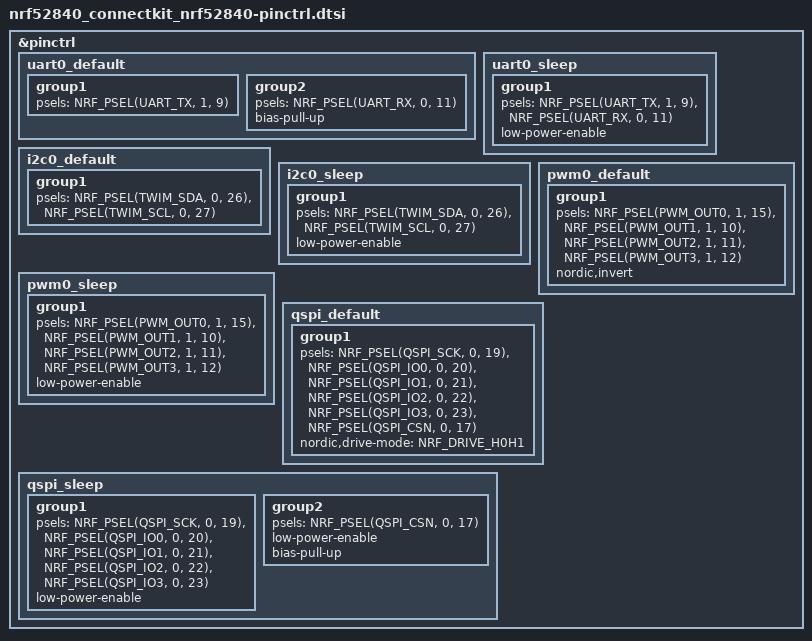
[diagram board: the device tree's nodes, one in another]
/*
 * Copyright (c) 2016-2025 Makerdiary <https://makerdiary.com>
 * SPDX-License-Identifier: Apache-2.0
 */

&pinctrl {
	uart0_default: uart0_default {
		group1 {
			psels = <NRF_PSEL(UART_TX, 1, 9)>;
		};
		group2 {
			psels = <NRF_PSEL(UART_RX, 0, 11)>;
			bias-pull-up;
		};
	};

	uart0_sleep: uart0_sleep {
		group1 {
			psels = <NRF_PSEL(UART_TX, 1, 9)>,
				<NRF_PSEL(UART_RX, 0, 11)>;
			low-power-enable;
		};
	};

	i2c0_default: i2c0_default {
		group1 {
			psels = <NRF_PSEL(TWIM_SDA, 0, 26)>,
				<NRF_PSEL(TWIM_SCL, 0, 27)>;
		};
	};

	i2c0_sleep: i2c0_sleep {
		group1 {
			psels = <NRF_PSEL(TWIM_SDA, 0, 26)>,
				<NRF_PSEL(TWIM_SCL, 0, 27)>;
			low-power-enable;
		};
	};

	pwm0_default: pwm0_default {
		group1 {
			psels = <NRF_PSEL(PWM_OUT0, 1, 15)>,
				<NRF_PSEL(PWM_OUT1, 1, 10)>,
				<NRF_PSEL(PWM_OUT2, 1, 11)>,
				<NRF_PSEL(PWM_OUT3, 1, 12)>;
			nordic,invert;
		};
	};

	pwm0_sleep: pwm0_sleep {
		group1 {
			psels = <NRF_PSEL(PWM_OUT0, 1, 15)>,
				<NRF_PSEL(PWM_OUT1, 1, 10)>,
				<NRF_PSEL(PWM_OUT2, 1, 11)>,
				<NRF_PSEL(PWM_OUT3, 1, 12)>;
			low-power-enable;
		};
	};

	qspi_default: qspi_default {
		group1 {
			psels = <NRF_PSEL(QSPI_SCK, 0, 19)>,
				<NRF_PSEL(QSPI_IO0, 0, 20)>,
				<NRF_PSEL(QSPI_IO1, 0, 21)>,
				<NRF_PSEL(QSPI_IO2, 0, 22)>,
				<NRF_PSEL(QSPI_IO3, 0, 23)>,
				<NRF_PSEL(QSPI_CSN, 0, 17)>;
			nordic,drive-mode = <NRF_DRIVE_H0H1>;
		};
	};

	qspi_sleep: qspi_sleep {
		group1 {
			psels = <NRF_PSEL(QSPI_SCK, 0, 19)>,
				<NRF_PSEL(QSPI_IO0, 0, 20)>,
				<NRF_PSEL(QSPI_IO1, 0, 21)>,
				<NRF_PSEL(QSPI_IO2, 0, 22)>,
				<NRF_PSEL(QSPI_IO3, 0, 23)>;
			low-power-enable;
		};
		group2 {
			psels = <NRF_PSEL(QSPI_CSN, 0, 17)>;
			low-power-enable;
			bias-pull-up;
		};
	};
};
